# STM8S208C6 register map
Vendor: STMicroelectronics; Series: STM8S/STM8AF, medium density; File version: 1.0
Mainstream Performance line 8-bit MCU with 32 Kbytes Flash, 24 MHz CPU, integrated EEPROM
CPU: other r1p0, big endian, no MPU, no FPU, 4 interrupt priority bits
Registers are 8-bit, read-write, reset 0x0 unless marked. A register's access mark holds for its fields unless they carry their own. Offsets are from the block's base; lines under a group give offsets from that group; [hi:lo] are bit positions; {n}, {i} and the like mark numbered series; 'fields as' and 'values as' point back to an identical list; <NAME> marks a mode.

## Memory map
0x00004800 OPT blocks up to offset 0x80
0x00005000 PORTA size 0x5
0x00005005 PORTB size 0x5
0x0000500A PORTC size 0x5
0x0000500F PORTD size 0x5
0x00005014 PORTE size 0x5
0x00005019 PORTF size 0x5
0x0000501E PORTG size 0x5
0x00005023 PORTH size 0x5
0x00005028 PORTI size 0x5
0x0000505A FLASH blocks up to offset 0xB
0x000050A0 ITC blocks up to offset 0x2ED8
0x000050B3 RST size 0x1
0x000050C0 CLK blocks up to offset 0xE
0x000050D1 WWDG size 0x2
0x000050E0 IWDG size 0x3
0x000050F0 AWU size 0x3
0x000050F3 BEEP size 0x1
0x00005200 SPI size 0x8
0x00005210 I2C blocks up to offset 0xF
0x00005230 UART1 size 0xB
0x00005240 UART3 blocks up to offset 0xA
0x00005250 TIM1 size 0x20
0x00005300 TIM2 size 0x15
0x00005320 TIM3 size 0x11
0x00005340 TIM4 size 0x7
0x00005400 ADC2 size 0x8
0x00005420 CAN size 0x18
0x00007F00 CPU blocks up to offset 0x61
0x00007F80 SWIM size 0x1
0x00007F90 DM size 0xB

## Interrupts
1 Interrupt_IRQ1 (AWU) — Interrupt_IRQ1 interrupt
2 Interrupt_IRQ2 (CLK, ITC) — Interrupt_IRQ2 interrupt
8 Interrupt_IRQ8 (CAN) — Interrupt_IRQ8 interrupt
9 Interrupt_IRQ9 (CAN) — Interrupt_IRQ9 interrupt
10 Interrupt_IRQ10 (SPI) — Interrupt_IRQ10 interrupt
11 Interrupt_IRQ11 (TIM1) — Interrupt_IRQ11 interrupt
12 Interrupt_IRQ12 (TIM1) — Interrupt_IRQ12 interrupt
13 Interrupt_IRQ13 (TIM2) — Interrupt_IRQ13 interrupt
14 Interrupt_IRQ14 (TIM2) — Interrupt_IRQ14 interrupt
15 Interrupt_IRQ15 (TIM3) — Interrupt_IRQ15 interrupt
16 Interrupt_IRQ16 (TIM3) — Interrupt_IRQ16 interrupt
17 Interrupt_IRQ17 (UART1) — Interrupt_IRQ17 interrupt
18 Interrupt_IRQ18 (UART1) — Interrupt_IRQ18 interrupt
19 Interrupt_IRQ19 (I2C) — Interrupt_IRQ19 interrupt
20 Interrupt_IRQ20 (UART3) — Interrupt_IRQ20 interrupt
21 Interrupt_IRQ21 (UART3) — Interrupt_IRQ21 interrupt
22 Interrupt_IRQ22 (ADC2) — Interrupt_IRQ22 interrupt
23 Interrupt_IRQ23 (TIM4) — Interrupt_IRQ23 interrupt
24 Interrupt_IRQ24 (FLASH) — Interrupt_IRQ24 interrupt

## ADC2
Base 0x00005400
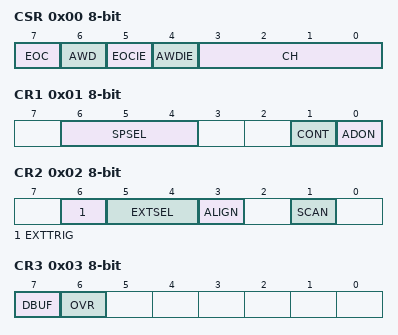
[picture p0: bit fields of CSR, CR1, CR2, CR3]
0x00 CSR — ADC control/status register
  [7] EOC, [6] AWD, [5] EOCIE, [4] AWDIE, [3:0] CH
0x01 CR1 — ADC configuration register 1
  [6:4] SPSEL, [1] CONT, [0] ADON
0x02 CR2 — ADC configuration register 2
  [6] EXTTRIG, [5:4] EXTSEL, [3] ALIGN, [1] SCAN
0x03 CR3 — ADC configuration register 3
  [7] DBUF, [6] OVR
0x04 DRH — ADC data register high
  [7:0] DH
0x05 DRL — ADC data register low
  [7:0] DL
0x06 TDRH — ADC Schmitt trigger disable register high
  [7:0] TD
0x07 TDRL — ADC Schmitt trigger disable register low
  [7:0] TL

## AWU
Base 0x000050F0
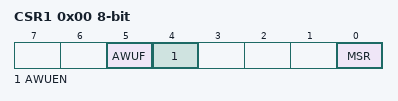
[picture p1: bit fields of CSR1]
0x00 CSR1 — AWU control/status register 1
  [5] AWUF, [4] AWUEN, [0] MSR
0x01 APR reset 0x3F — AWU asynchronous prescaler buffer register
  [5:0] APR
0x02 TBR — AWU timebase selection register
  [3:0] AWUTB

## BEEP
Base 0x000050F3
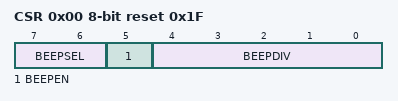
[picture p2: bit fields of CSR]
0x00 CSR reset 0x1F — BEEP control/status register
  [7:6] BEEPSEL, [5] BEEPEN, [4:0] BEEPDIV

## CLK
Base 0x000050C0
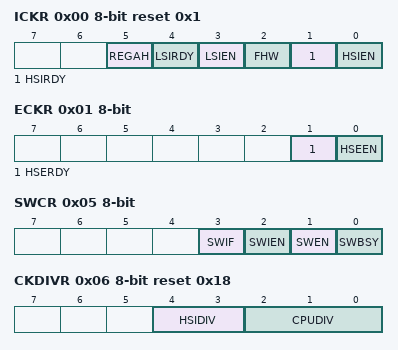
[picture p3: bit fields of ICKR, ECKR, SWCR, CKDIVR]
0x00 ICKR reset 0x1 — Internal clock control register
  [5] REGAH, [4] LSIRDY, [3] LSIEN, [2] FHW, [1] HSIRDY, [0] HSIEN
0x01 ECKR — External clock control register
  [1] HSERDY, [0] HSEEN
0x03 CMSR reset 0xE1 — Clock master status register
  [7:0] CKM
0x04 SWR reset 0xE1 — Clock master switch register
  [7:0] SWI
0x05 SWCR — Clock switch control register
  [3] SWIF, [2] SWIEN, [1] SWEN, [0] SWBSY
0x06 CKDIVR reset 0x18 — Clock divider register
  [4:3] HSIDIV, [2:0] CPUDIV
0x07 PCKENR1 reset 0xFF — Peripheral clock gating register 1
  [7:0] PCKEN
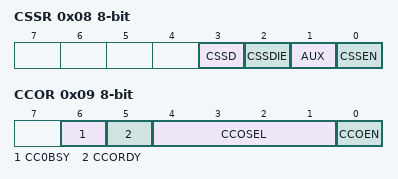
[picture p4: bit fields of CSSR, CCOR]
0x08 CSSR — Clock security system register
  [3] CSSD, [2] CSSDIE, [1] AUX, [0] CSSEN
0x09 CCOR — Configurable clock control register
  [6] CC0BSY, [5] CCORDY, [4:1] CCOSEL, [0] CCOEN
0x0A PCKENR2 reset 0xFF — Peripheral clock gating register 2
  [7:0] PCKEN2
0x0B CANCCR — CAN clock control register
  [2:0] CANDIV
0x0C HSITRIMR — HSI clock calibration trimming register
  [3:0] HSITRIM
0x0D SWIMCCR — SWIM clock control register
  [0] SWIMCLK
